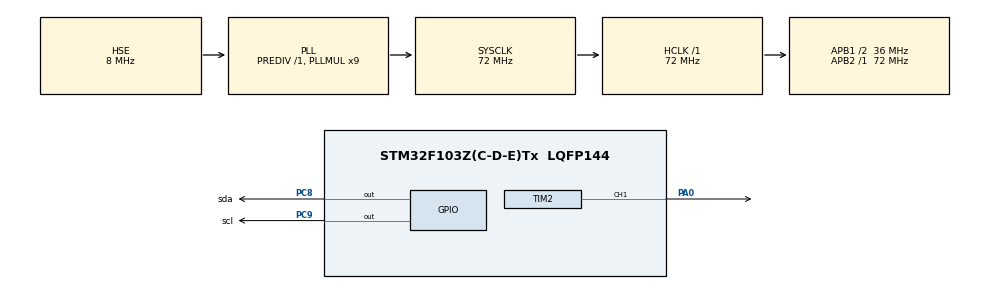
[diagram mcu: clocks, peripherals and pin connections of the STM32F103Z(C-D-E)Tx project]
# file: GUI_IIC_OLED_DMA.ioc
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Dma.MEMTOMEM.0.Direction=DMA_MEMORY_TO_MEMORY
Dma.MEMTOMEM.0.Instance=DMA1_Channel1
Dma.MEMTOMEM.0.MemDataAlignment=DMA_MDATAALIGN_BYTE
Dma.MEMTOMEM.0.MemInc=DMA_MINC_ENABLE
Dma.MEMTOMEM.0.Mode=DMA_NORMAL
Dma.MEMTOMEM.0.PeriphDataAlignment=DMA_PDATAALIGN_BYTE
Dma.MEMTOMEM.0.PeriphInc=DMA_PINC_ENABLE
Dma.MEMTOMEM.0.Priority=DMA_PRIORITY_VERY_HIGH
Dma.Request0=MEMTOMEM
Mcu.Family=STM32F1
Mcu.Name=STM32F103Z(C-D-E)Tx
Mcu.Package=LQFP144
NVIC.PriorityGroup=NVIC_PRIORITYGROUP_4
OSC_IN.Mode=HSE-External-Oscillator
OSC_IN.Signal=RCC_OSC_IN
OSC_OUT.Mode=HSE-External-Oscillator
OSC_OUT.Signal=RCC_OSC_OUT
PA0-WKUP.Signal=S_TIM2_CH1_ETR
PA13.Mode=Serial_Wire
PA13.Signal=SYS_JTMS-SWDIO
PA14.Mode=Serial_Wire
PA14.Signal=SYS_JTCK-SWCLK
PC14-OSC32_IN.Mode=LSE-External-Oscillator
PC14-OSC32_IN.Signal=RCC_OSC32_IN
PC15-OSC32_OUT.Mode=LSE-External-Oscillator
PC15-OSC32_OUT.Signal=RCC_OSC32_OUT
PC8.GPIO_Label=sda
PC8.Signal=GPIO_Output
PC9.GPIO_Label=scl
PC9.Signal=GPIO_Output
ProjectManager.HeapSize=0x200
ProjectManager.StackSize=0x400
ProjectManager.TargetToolchain=MDK-ARM V5
RCC.AHBFreq_Value=72000000
RCC.APB1CLKDivider=RCC_HCLK_DIV2
RCC.APB1Freq_Value=36000000
RCC.APB1TimFreq_Value=72000000
RCC.APB2Freq_Value=72000000
RCC.APB2TimFreq_Value=72000000
RCC.HCLKFreq_Value=72000000
RCC.PLLMUL=RCC_PLL_MUL9
RCC.PLLSourceVirtual=RCC_PLLSOURCE_HSE
RCC.SYSCLKFreq_VALUE=72000000
RCC.SYSCLKSource=RCC_SYSCLKSOURCE_PLLCLK
RCC.USBFreq_Value=72000000
SH.S_TIM2_CH1_ETR.0=TIM2_CH1,PWM Generation1 CH1
TIM2.AutoReloadPreload=TIM_AUTORELOAD_PRELOAD_ENABLE
TIM2.Channel-PWM\ Generation1\ CH1=TIM_CHANNEL_1
TIM2.Period=1000
TIM2.Prescaler=71
TIM2.Pulse-PWM\ Generation1\ CH1=500
board=custom

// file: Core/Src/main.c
/* USER CODE BEGIN Header */
/**
  ******************************************************************************
  * @file           : main.c
  * @brief          : Main program body
  ******************************************************************************
  * @attention
  *
  * Copyright (c) 2022 STMicroelectronics.
  * All rights reserved.
  *
  * This software is licensed under terms that can be found in the LICENSE file
  * in the root directory of this software component.
  * If no LICENSE file comes with this software, it is provided AS-IS.
  *
  ******************************************************************************
  */
/* USER CODE END Header */
#include "main.h"
#include "dma.h"
#include "tim.h"
#include "gpio.h"

/* USER CODE BEGIN Includes */

#include "lcmBase.h"
#include "windows.h"
#include "FONT8_8.h"
#include "font5_7.h"
#include "FONT24_32.h"
#include "GUI_BASIC.h"
#include "Loadbit.h"
#include "menu.h"
#include "OLED.h"
#include "spline.h"

/* USER CODE END Includes */

/* USER CODE BEGIN PV */
extern  WINDOWS A;
extern uint8_t  const  button_cancle1[];
extern PointXY empty_point[10];//定义十个点
/* USER CODE END PV */

void SystemClock_Config(void);

int main(void)
{

  /* MCU Configuration--------------------------------------------------------*/

  /* Reset of all peripherals, Initializes the Flash interface and the Systick. */
  HAL_Init();

  /* Configure the system clock */
  SystemClock_Config();

  /* Initialize all configured peripherals */
  MX_GPIO_Init();
  MX_DMA_Init();
  MX_TIM2_Init();
  /* USER CODE BEGIN 2 */
	HAL_TIM_PWM_Start(&htim2,TIM_CHANNEL_1);
//	LCM_DispIni();//OLED初始化
//	setA();
////	GUI_WindowsDraw(&A);//画窗口
//
//	//GUI_PutNoStr(0, 0,"fuck you", 8);
//	//GUI_PutNoStr8_8(0, 0,"fuck you", 8);//显示字符串
//	 //GUI_PutString24_32(0,0,"0+0");//只能显示数字和运算符
//	//	GUI_Line(0,32,127,32,1);
//	//set();//设置放样曲线的点
//	//GUI_Spline(empty_point,5,1);//产生放样曲线
//		//OLED_Scroll();//滚动
////	 GUI_Arc(64,32,30,0,180,1);
////	 GUI_Arc(64,32,30,181,359,1);//画圆分上下两部分画
//			//GUI_Ellipse(10,110,0,63,1);//画椭圆
//			//GUI_Pieslice(64,32,10,0,270,1);//画扇形
//	 //GUI_Button49x14(64,32,(uint8_t*)button_cancle1);//画一个没用的按键
//
//	GUI_Square(90,10, 10,1);//画正方形
//
//	OLED_Refresh_Gram();
  /* USER CODE END 2 */

  /* Infinite loop */
  /* USER CODE BEGIN WHILE */
  while (1)
  {
//		OLED_Scroll_speed();
//		//GUI_PutNoStr8_8(5, 0,"speed", 8);
//		GUI_Line(40,0, 40,63, 1);
//		//GUI_WindowsDraw(&A);
//		OLED_Refresh_Gram();
    /* USER CODE END WHILE */

  }
}

void SystemClock_Config(void)
{
  RCC_OscInitTypeDef RCC_OscInitStruct = {0};
  RCC_ClkInitTypeDef RCC_ClkInitStruct = {0};

  /** Initializes the RCC Oscillators according to the specified parameters
  * in the RCC_OscInitTypeDef structure.
  */
  RCC_OscInitStruct.OscillatorType = RCC_OSCILLATORTYPE_HSE;
  RCC_OscInitStruct.HSEState = RCC_HSE_ON;
  RCC_OscInitStruct.HSEPredivValue = RCC_HSE_PREDIV_DIV1;
  RCC_OscInitStruct.HSIState = RCC_HSI_ON;
  RCC_OscInitStruct.PLL.PLLState = RCC_PLL_ON;
  RCC_OscInitStruct.PLL.PLLSource = RCC_PLLSOURCE_HSE;
  RCC_OscInitStruct.PLL.PLLMUL = RCC_PLL_MUL9;
  if (HAL_RCC_OscConfig(&RCC_OscInitStruct) != HAL_OK)
  {
    Error_Handler();
  }

  /** Initializes the CPU, AHB and APB buses clocks
  */
  RCC_ClkInitStruct.ClockType = RCC_CLOCKTYPE_HCLK|RCC_CLOCKTYPE_SYSCLK
                              |RCC_CLOCKTYPE_PCLK1|RCC_CLOCKTYPE_PCLK2;
  RCC_ClkInitStruct.SYSCLKSource = RCC_SYSCLKSOURCE_PLLCLK;
  RCC_ClkInitStruct.AHBCLKDivider = RCC_SYSCLK_DIV1;
  RCC_ClkInitStruct.APB1CLKDivider = RCC_HCLK_DIV2;
  RCC_ClkInitStruct.APB2CLKDivider = RCC_HCLK_DIV1;

  if (HAL_RCC_ClockConfig(&RCC_ClkInitStruct, FLASH_LATENCY_2) != HAL_OK)
  {
    Error_Handler();
  }
}

void Error_Handler(void)
{
  __disable_irq();
  while (1)
  {
  }
}
